AUTOSAR XML (schema 00049)
package /Application/DltConfig
  dlt log channel to process mapping DltLogChannelToProcessMapping_SOA_RearCurtain_TO_SOA_RearCurtain: dlt-log-channel=SOA_RearCurtain, process=SOA_RearCurtain
package /Application/Executable
  executable SOA_RearCurtain: category=APPLICATION_LEVEL, logging-behavior=USES-LOGGING, reporting-behavior=REPORTS-EXECUTION-STATE, version=1.0.0
    root sw component prototype AA: application-type=SOA_RearCurtain
package /Application/Manifest
  service instance to port prototype mapping SOA_RearCurtain_AA_PPort_SOA_RearCurtain: port-prototype=AA.PPort_SOA_RearCurtain, process=SOA_RearCurtain, service-instance=Provider_SoaRcurtain
  service instance to port prototype mapping SOA_RearCurtain_AA_RPort_Zone1VehicleInfo: port-prototype=AA.RPort_Zone1VehicleInfo, process=SOA_RearCurtain, service-instance=Consumer_SoaRcurtain_VehicleInfo
  service instance to port prototype mapping SOA_RearCurtain_AA_RPort_Zone3Rcurtain: port-prototype=AA.RPort_Zone3Rcurtain, process=SOA_RearCurtain, service-instance=Consumer_Zone3Rcurtain
package /Application/Package/SOA_RearCurtain/SoftwareCluster_1_0_0
  software cluster SOA_RearCurtain_SoftwareCluster: category=APPLICATION_LAYER, contained-ar-element=SOA_RearCurtain, contained-package-element=[SOA_RearCurtain_AA_PPort_SOA_RearCurtain, SOA_RearCurtain_AA_RPort_Zone3Rcurtain], contained-process=SOA_RearCurtain, vendor-id=79, vendor-signature=ParaCertificate, version=1.0.0
package /Application/Package/SOA_RearCurtain/SoftwareCluster_1_0_1
  software cluster SOA_RearCurtain_SoftwareCluster: category=APPLICATION_LAYER, contained-ar-element=SOA_RearCurtain, contained-package-element=[SOA_RearCurtain_AA_PPort_SOA_RearCurtain, SOA_RearCurtain_AA_RPort_Zone3Rcurtain], contained-process=SOA_RearCurtain, vendor-id=79, vendor-signature=ParaCertificate, version=1.0.1
package /Application/Package/SOA_RearCurtain/SoftwareCluster_1_0_2
  software cluster SOA_RearCurtain_SoftwareCluster: category=APPLICATION_LAYER, contained-ar-element=SOA_RearCurtain, contained-package-element=[SOA_RearCurtain_AA_PPort_SOA_RearCurtain, SOA_RearCurtain_AA_RPort_Zone3Rcurtain], contained-process=SOA_RearCurtain, vendor-id=79, vendor-signature=ParaCertificate, version=1.0.2
package /Application/Package/SOA_RearCurtain/SoftwarePackage
  software package SOA_RearCurtain_InstallSoftwarePackage_1_0_0: action-type=INSTALL, compressed-software-package-size=0, maximum-supported-ucm-version=1.0.0, minimum-supported-ucm-version=1.0.0, packager-id=79, packager-signature=ParaCertificate, post-verification-reboot=false, pre-activate=SC.Off, pre-activation-reboot=false, software-cluster=SoftwareCluster_1_0_0/SOA_RearCurtain_SoftwareCluster, uncompressed-software-cluster-size=0, verify=SC.Verify
  software package SOA_RearCurtain_RemoveSoftwarePackage_1_0_2: action-type=REMOVE, compressed-software-package-size=0, maximum-supported-ucm-version=1.0.0, minimum-supported-ucm-version=1.0.0, packager-id=79, packager-signature=ParaCertificate, post-verification-reboot=false, pre-activate=SC.Off, pre-activation-reboot=false, software-cluster=SoftwareCluster_1_0_2/SOA_RearCurtain_SoftwareCluster, uncompressed-software-cluster-size=0, verify=SC.Verify
  software package SOA_RearCurtain_UpdateSoftwarePackage_1_0_1: action-type=UPDATE, compressed-software-package-size=0, maximum-supported-ucm-version=1.0.0, minimum-supported-ucm-version=1.0.0, packager-id=79, packager-signature=ParaCertificate, post-verification-reboot=false, pre-activate=SC.Off, pre-activation-reboot=false, software-cluster=SoftwareCluster_1_0_1/SOA_RearCurtain_SoftwareCluster, uncompressed-software-cluster-size=0, verify=SC.Verify
package /Application/Package/SOA_RearCurtain/VehiclePackage
  vehicle package SOA_RearCurtain_InstallVehiclePackage_1_0_0: vehicle-driver-notification{approval-required=true, notification-state=PROCESS}, packager-signature=ParaCertificate
    rollout-qualifications:
      vehicle rollout step RolloutQualification0
        ucm-processings:
          ucm step UcmProcessing0: ucm=SOA_RearCurtain_InstallVehiclePackage_1_0_0/EEVP_UCM
            software package step SoftwarePackageStep0: process=SOA_RearCurtain_InstallSoftwarePackage_1_0_0, transfers=software-package-storing={storing=UCM, transfer=SOA_RearCurtain_InstallSoftwarePackage_1_0_0}
    ucm description EEVP_UCM: identifier=EEVP_UCM
  vehicle package SOA_RearCurtain_RemoveVehiclePackage_1_0_2: vehicle-driver-notification{approval-required=true, notification-state=PROCESS}, packager-signature=ParaCertificate
    rollout-qualifications:
      vehicle rollout step RolloutQualification0
        ucm-processings:
          ucm step UcmProcessing0: ucm=SOA_RearCurtain_RemoveVehiclePackage_1_0_2/EEVP_UCM
            software package step SoftwarePackageStep0: process=SOA_RearCurtain_RemoveSoftwarePackage_1_0_2, transfers=software-package-storing={storing=UCM, transfer=SOA_RearCurtain_RemoveSoftwarePackage_1_0_2}
    ucm description EEVP_UCM: identifier=EEVP_UCM
  vehicle package SOA_RearCurtain_UpdateVehiclePackage_1_0_1: vehicle-driver-notification{approval-required=true, notification-state=PROCESS}, packager-signature=ParaCertificate
    rollout-qualifications:
      vehicle rollout step RolloutQualification0
        ucm-processings:
          ucm step UcmProcessing0: ucm=SOA_RearCurtain_UpdateVehiclePackage_1_0_1/EEVP_UCM
            software package step SoftwarePackageStep0: process=SOA_RearCurtain_UpdateSoftwarePackage_1_0_1, transfers=software-package-storing={storing=UCM, transfer=SOA_RearCurtain_UpdateSoftwarePackage_1_0_1}
    ucm description EEVP_UCM: identifier=EEVP_UCM
package /Application/Process
  process SOA_RearCurtain: executable=SOA_RearCurtain, pre-mapping=false, state-dependent-startup-config{function-group-state=[SC.On, SC.Verify], resource-group=DefaultResourceGroup, startup-config=SOA}
    process state machine SOA_RearCurtain: type=ProcessState
package /Application/SwComponent
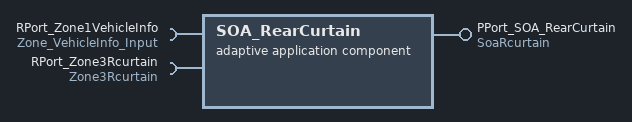
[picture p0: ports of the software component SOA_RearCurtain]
  adaptive application sw component type SOA_RearCurtain
    provide port PPort_SOA_RearCurtain: provided-interface=SoaRcurtain
    require port RPort_Zone1VehicleInfo: required-interface=Zone_VehicleInfo_Input
    require port RPort_Zone3Rcurtain: required-interface=Zone3Rcurtain
